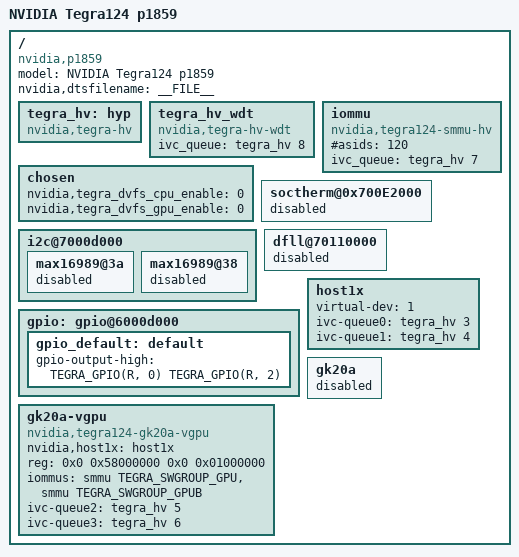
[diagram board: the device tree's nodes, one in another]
/*
 * arch/arm/boot/dts/tegra124-android-p1859-vm.dts
 *
 * Copyright (c) 2013-2014, NVIDIA CORPORATION.  All rights reserved.
 *
 * This program is free software; you can redistribute it and/or modify
 * it under the terms of the GNU General Public License as published by
 * the Free Software Foundation; version 2 of the License.
 *
 * This program is distributed in the hope that it will be useful, but WITHOUT
 * ANY WARRANTY; without even the implied warranty of MERCHANTABILITY or
 * FITNESS FOR A PARTICULAR PURPOSE.  See the GNU General Public License for
 * more details.
 *
 * You should have received a copy of the GNU General Public License along
 * with this program; if not, write to the Free Software Foundation, Inc.,
 * 51 Franklin Street, Fifth Floor, Boston, MA  02110-1301, USA.
 *
 */

 /dts-v1/;

/* This file is for Vibrante 3.0 Android */
/ {
	/* smmu and ivc drivers are called very early in the kernel init
	 * call sequence (core_initcall). smmu driver as such is a consumer
	 * of ivc and depends on it.
	 * Keeping the ivc node at the very top in the device tree ensures
	 * that probe for ivc is called before the smmu driver probe.
	 * Without this virtualized smmu driver probe will fail.
	 */
	tegra_hv: hyp {
		compatible = "nvidia,tegra-hv";
		status = "okay";
	};
};

#include "tegra124-p1859.dtsi"

/ {
        model = "NVIDIA Tegra124 p1859";
        compatible = "nvidia,p1859", "nvidia,tegra124";
        nvidia,dtsfilename = __FILE__;

	tegra_hv_wdt {
		compatible = "nvidia,tegra-hv-wdt";
		status = "okay";
		ivc_queue = <&tegra_hv 8>;
	};

	iommu {
		compatible = "nvidia,tegra124-smmu-hv";
		#asids = <120>;
		ivc_queue = <&tegra_hv 7>;
	};

	chosen {
		nvidia,tegra_dvfs_cpu_enable = <0>;
		nvidia,tegra_dvfs_gpu_enable = <0>;
	};

	soctherm@0x700E2000 {
		status = "disabled";
	};

	i2c@7000d000 {
		status = "okay";

		max16989@3a {
			status = "disabled";
		};

		max16989@38 {
			status = "disabled";
		};
	};

	dfll@70110000 {
		status = "disabled";
	};

	gpio: gpio@6000d000 {
		gpio_default: default {
		gpio-output-high = <TEGRA_GPIO(R, 0)
				TEGRA_GPIO(R, 2)>;
		};
	};

	host1x {
		virtual-dev = <1>;

		ivc-queue0 = <&tegra_hv 3>;
		ivc-queue1 = <&tegra_hv 4>;
	};

	gk20a {
		status = "disabled";
	};

	gk20a-vgpu {
		compatible = "nvidia,tegra124-gk20a-vgpu";
		nvidia,host1x = <&host1x>;
		reg = <0x0 0x58000000 0x0 0x01000000>;
		iommus = <&smmu TEGRA_SWGROUP_GPU &smmu TEGRA_SWGROUP_GPUB>;

		ivc-queue2 = <&tegra_hv 5>;
		ivc-queue3 = <&tegra_hv 6>;
	};
};
